# RL6955_IP_SVD register map
Vendor: Realtek
Registers are 32-bit, read-write, reset 0x0 unless marked. A register's access mark holds for its fields unless they carry their own. Offsets are from the block's base; [hi:lo] are bit positions; {n}, {i} and the like mark numbered series.

## AES_SHA_DMA_REG
Base 0x400C2000
Same registers: GDMA0_REG 0x41802000
{0x0+0x58*i} SAR{i} (i=0..7) — Channel {i} Source Address Register
  [31:0] SAR{i} — Source Address of DMA transfer.Updated after each source transfer. The SINC field in the CTLx register determines whether the address increments, or is left unchanged on every source transfer throughout the block transfer.
{0x4+0x58*i} CURR_SAR{i} ro (i=0..7) — The read back value is channel {i} source reading address at present
  [31:0] CURR_SAR{i} — The read back value is source reading address at present
{0x8+0x58*i} DAR{i} (i=0..7) — Channel {i} Destination Address Register
  [31:0] DAR{i} — Destination address of DMA transfer.Updated after each destination transfer. The DINC field in the CTLx register determines whether the address increments, or is left unchanged on every destination transfer throughout the block transfer.
{0xC+0x58*i} CURR_DAR{i} ro (i=0..7) — The read back value is channel {i} destination writing address at present
  [31:0] CURR_DAR{i} — The read back value is destination writing address at present
{0x10+0x58*i} LLP{i}_L (i=0..7) — Channel {i} low-32 bits Linked List Pointer Register
  [31:2] LLP{i}_L_LOC — Starting Address In Memory of next LLI if block chaining is enabled. Note that the two LSBs of the starting address are not stored because the address is assumed to be aligned to a 32-bit boundary.LLI accesses are always 32-bit accesses aligned to 32-bit boundaries and cannot be changed or programmed to anything other than 32-bit.
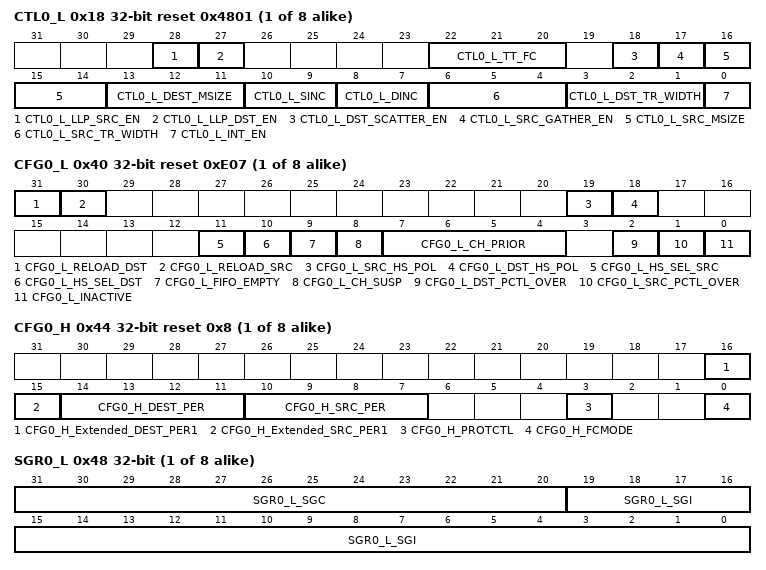
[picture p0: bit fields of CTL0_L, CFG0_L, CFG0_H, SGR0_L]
{0x18+0x58*i} CTL{i}_L reset 0x4801 (i=0..7) — Channel {i} low-32 bits Control Register
  [28] CTL{i}_L_LLP_SRC_EN — Block chanining is enabled on the source side only if the LLP_SRC_EN field id high and LLPx_L.LOC is non-zero; for more information,see 7.4.1.1 "Block Chaining Using Linked Lists" Dependencies:This field does not exist if the configuration parameterDMAC_CHx_MULTI_BLK_EN is not selected or if DMAC_CHx_HC_LLP is selected; in this case, the read-back value is always 0.
  [27] CTL{i}_L_LLP_DST_EN — Block chanining is enabled on the destination side only if the LLP_DST_EN field id high and LLPx_L.LOC is non-zero; for more information,see 7.4.1.1 "Block Chaining Using Linked Lists" Dependencies:This field does not exist if the configuration parameterDMAC_CHx_MULTI_BLK_EN is not selected or if DMAC_CHx_HC_LLP is selected; in this case, the read-back value is always 0.
  [22:20] CTL{i}_L_TT_FC — Transfer Type and Flow Control.The following transfer types are supported. • Memory to Memory • Memory to Peripheral • Peripheral to Memory • Peripheral to Peripheral Flow Control can be assigned to the RTK_DMAC, the source peripheral, or the destination peripheral. Table 6-4 lists the decoding for this field. For more information on transfer types and flow control, refer to "Setup/Operation of RTK_DMAC Transfers". Reset Value: 3'h0 Dependencies: If hardware handshake isn't support, then TT_FC can only be set to 3'b0. TT_FC[2] can only be read.
  [18] CTL{i}_L_DST_SCATTER_EN — Destination scatter enable bit:0 = Scatter disabled1 = Scatter enabledScatter on the destination side is applicable only when the CTLx_L.DINC bit indicates an incrementing address control and DARx should be aligned with DST_TR_WIDTH. Dependencies: This field does not exist if DMAC_CHx_DST_SCA_EN is not selected.
  [17] CTL{i}_L_SRC_GATHER_EN — Source gather enable bit: 0 = Gather disabled 1 = Gather enabled Gather on the source side is applicable only when the CTLx_L.SINC bit indicates an incrementing address control and SARx should be aligned with SRC_TR_WIDTH. Dependencies: This field does not exist if DMAC_CHx_SRC_GAT_EN is not selected.
  [16:14] CTL{i}_L_SRC_MSIZE — Source Burst Transaction Length. Number of data items, each of width CTLx_L.SRC_TR_WIDTH if source is not memory, otherwise each of width DMAC_TR_WIDTH_DEFAULT, to be read from the source every time a source burst transaction request is made from either the corresponding hardware or software handshaking interface. Read burst transaction length on bus (ARLen) will not exceed this value, but may be less than this value. If SINC is setted to "no change", this value should not be greater than 16 to conform to the AXI protocol. If enabled 'DMAC_CHx_MSIZE_BIGGER_THAN_FIFO_DEPTH' feature, to improve performance, can set CTLx_L.SRC_MSIZE to a high value to make DMAC send longer burst length command. But to avoid deadlock, if Source slave and Destination slave is the same slave, should not set CTLx_L.SRC_MSIZE over than FIFO_depth; Table 6-2-0 lists the decoding for this field.
  [13:11] CTL{i}_L_DEST_MSIZE — Destination Burst Transaction Length. Number of data items, each of width DATA_WIDTH, to be written to the destination every time a destination burst transaction request is made from either the corresponding hardware or software handshaking interface. Write burst transaction length on bus (AWLen) will not exceed this value, but may be less than this value. If DINC is setted to "no change", this value should not be greater than 16 to conform to the AXI protocol. If enabled 'DMAC_CHx_MSIZE_BIGGER_THAN_FIFO_DEPTH' feature, to improve performance, can set CTLx_L.SRC_MSIZE to a high value to make DMAC send longer burst length command. But to avoid deadlock, if Source slave and Destination slave is the same slave, should not set CTLx_L.SRC_MSIZE over than FIFO_depth; Table 6-2-1 lists the decoding for this field.
  [10:9] CTL{i}_L_SINC — Source Address Increment. Indicates whether to increment the source address on every source transfer. If the device is fetching data from a source peripheral FIFO with a fixed address, then set this field to "No change."If source is memory appointed by CTLx_L.TT_FC, and set SINC=No change, then SRC_TR_WIDTH must be set to BUS width. And DMAC will read data from the fixed memory address until block transfer finish, but It is not recommended to read memory like this, because some memory controller not support fixed burst transaction and may transform the fixed burst transaction to incremental burst transaction. 00 = Increment 01 =Not support 1x = No change NOTE: Incrementing is done for alignment to the next CTLx_L.SRC_TR_WIDTH boundary.
  [8:7] CTL{i}_L_DINC — Destination Address Increment. Indicates whether to increment destination address on every destination transfer. If your device is writing data to a destination peripheral FIFO with a fixed address, then set this field to "No change."If destination is memory appointed by CTLx_L.TT_FC, and set DINC=No change, then DST_TR_WIDTH must be set to BUS width. And DMAC will write data to the fixed memory address until block transfer finish, but It is not recommended to write memory like this, because some memory controller not support fixed burst transaction and may transform the fixed burst transaction to incremental burst transaction. 00 = Increment 01=Not Support 1x = No change NOTE: Incrementing is done for alignment to the next CTLx_L.DST_TR_WIDTH boundary.
  [6:4] CTL{i}_L_SRC_TR_WIDTH — Source Transfer Width. Table 6-3 lists the decoding for this field.It can't be mapped to AXI bus data width directly. Since AXI bus data width is fixed (such as 32bit/64bit), AXI use byte enable signal for byte/half word transfer (still burst). So, the SRC_TR_WIDTH is only used for total block data size calculation and streaming mode byte/half word transfer (for FIFO transfer). Note: SRC_TR_WIDTH must not be bigger than BUS width.
  [3:1] CTL{i}_L_DST_TR_WIDTH — Destination Transfer Width.Table 6-3 lists the decoding for this field. It can't be mapped to AXI bus data width directly. For a non-memory peripheral, typically the peripheral (destination) FIFO width.Note: DST_TR_WIDTH must not be bigger than BUS width
  [0] CTL{i}_L_INT_EN — Interrupt Enable Bit. If set, then all interrupt-generating sources are enabled. Functions as a global mask bit for all interrupts for the channel; raw* interrupt registers still assert if CTLx_L.INT_EN = 0.
{0x1C+0x58*i} CTL{i}_H access per field reset 0x2 (i=0..7) — Channel {i} high-32 bits Control Register
  [31:0] CTL{i}_H_TRANS_DATA_CNT ro — Data Transfered Count.Once the transfer starts, the read-back value is the total number of data bytes already write to destination memory or peripheral.
  [20:0] CTL{i}_H_BLOCK_TS wo — Block Transfer Size.When the RTK_DMAC is the flow controller, the user writes this field before the channel is enabled in order to indicate the block size. The number programmed into BLOCK_TS indicates the total number of single transactions to perform for every block transfer; a single transaction is mapped to a single AXI beat. This field is write-only, number of block size programmed into CTLx_H.BLOCK_TS can be read from SGRx_H.BLOCK_TS_L and DSRx_H.BLOCK_TS_H. Width: The width of the single transaction is determined by CTLX_L.SRC_TR_WIDTH.When the source or destination peripheral is assigned as the flow controller, then the maximum block size that can be read back saturates at DMAC_CHx_MAX_BLK_SIZE, but the actual block size can be greater. b = log2(DMAC_CHx_MAX_BLK_SIZE + 1) -1
{0x40+0x58*i} CFG{i}_L access per field reset 0xE07 (i=0..7) — Channel {i} low-32 bits Configuration Register
  [31] CFG{i}_L_RELOAD_DST rw — Automatic Destination Reload. The DARx register can be automatically reloaded from its initial value at the end of every block for multi-block transfers. A new block transfer is then initiated.This register does not exist if the configuration parameter DMAC_CHx_MULTI_BLK_EN is not selected; in this case, the read-back value is always 0.
  [30] CFG{i}_L_RELOAD_SRC rw — Automatic Source Reload. The SARx register can be automatically reloaded from its initial value at the end of every block for multi-block transfers. A new block transfer is then initiated. This field does not exist if the configuration parameter DMAC_CHx_MULTI_BLK_EN is not selected; in this case, the read-back value is always 0.
  [19] CFG{i}_L_SRC_HS_POL rw — Source Handshaking Interface Polarity. 0 = Active high 1 = Active low
  [18] CFG{i}_L_DST_HS_POL rw — Destination Handshaking Interface Polarity. 0 = Active high 1 = Active low For information on this, refer to "Handshaking Interface" .
  [11] CFG{i}_L_HS_SEL_SRC rw — Source Software or Hardware Handshaking Select. This register selects which of the handshaking interfaces - hardware or software - is active for source requests on this channel. 0 = Hardware handshaking interface. Software-initiated transaction requests are ignored. 1 = Software handshaking interface. Hardware-initiated transaction requests are ignored. If the source peripheral is memory, then this bit is ignored.
  [10] CFG{i}_L_HS_SEL_DST rw — Destination Software or Hardware Handshaking Select. This register selects which of the handshaking interfaces - hardware or software - is active for destination requests on this channel. 0 = Hardware handshaking interface. Software-initiated transaction requests are ignored. 1 = Software handshaking interface. Hardware- initiated transaction requests are ignored. If the destination peripheral is memory, then this bit is ignored.
  [9] CFG{i}_L_FIFO_EMPTY ro — Indicates if there is data left in the channel FIFO. 1 = Channel FIFO empty 0 = Channel FIFO not empty
  [8] CFG{i}_L_CH_SUSP rw — Channel Suspend. Suspends all DMA data transfers from the source until this bit is cleared. There is no guarantee that the current transaction will complete. Can also be used in conjunction with CFGx_l.INACTIVE to cleanly disable a channel without losing any data. 0 = Not suspended 1 = Suspend DMA transfer from the source. This field will be reset to 0 after "Disabling a Channel Prior to Transfer Completion" automatically by hardware.For more information, refer to "7.7 Disabling a Channel Prior to Transfer Completion" . Note: if user not define DMAC_CH*_SUPPORT_SUSPEND, it only can be readed.
  [7:4] CFG{i}_L_CH_PRIOR rw — Channel priority. RTK DMAC supports three kinds of channel priority now, fixed priority, round robin priority and programmable priority. The default way is fixed priority to reduce area, and channel0 has the highest priority, channel15 has the lowest priority. Changing the definition of parameter FIX_PRIORITY or Programmable_PRIORITY can change priority way. If RTK DMAC is configured to support Programmable priority, this field will be used to set priority between channels. CH_PRIOR's legal value is 0 ~ (DMAC_NUM_CHANNELS-1), and 0 is the highest priority value, (DMAC_NUM_CHANNELS-1) is the lowest priroty value. If more than one channel are set with the same priroty value, the channel with small channel number index has higher priority. If DMAC is configured to support fix priority or round-robin priority, this field is not exist. Note: if user not define ProgrammablePriority, it only can be readed.
  [2] CFG{i}_L_DST_PCTL_OVER ro — DMA destination bus protocol finish, indicating the current write command has finished.
  [1] CFG{i}_L_SRC_PCTL_OVER ro — DMA Source bus protocol finish, indicating the current read command has finished.
  [0] CFG{i}_L_INACTIVE ro — Indicates if the channel is inactive. Can be used in conjunction with CFGx_L.CH_SUSP to cleanly disable a channel when destination is peripheral. For more information, refer to "Disabling a Channel Prior to Transfer Completion" . 1 = Channel Inactive for axi interface 0 = Channel not Inactive for axi interface
{0x44+0x58*i} CFG{i}_H reset 0x8 (i=0..7) — Channel {i} high-32 bits Configuration Register
  [16] CFG{i}_H_Extended_DEST_PER1 — The extened 4th bit of DEST_PER when hardware handshake interfaces number is configured to 32.
  [15] CFG{i}_H_Extended_SRC_PER1 — The extened 4th bit of SRC_PER when hardware handshake interfaces number is configured to 32.
  [14:11] CFG{i}_H_DEST_PER — Assigns a hardware handshaking interface(0 - DMAC_NUM_HS_INT-1) to the destination of channel x if the FGx.HS_SEL_DST field is 0; otherwise, this field is ignored. The channel can then communicate with the destinationperipheral connected to that interface through the assignedhardware handshaking interface. NOTE1: For correct DMA operation, only one peripheral (sourceor destination) should be assigned to the same handshaking interface NOTE2: This field does not exist if the configuration parameterDMAC_NUM_HS_INT is set to 0.
  [10:7] CFG{i}_H_SRC_PER — Assigns a hardware handshaking interface(0 - DMAC_NUM_HS_INT-1) to the source of channel x if the CFGx.HS_SEL_SRC field is 0; otherwise, this field is ignored. The channel can then communicate with the source peripheral connected to that interface through the assigned hardware handshaking interface. NOTE1: For correct RTK_DMAC operation, only one peripheral (source or destination) should be assigned to the same handshaking interface. NOTE2: This field does not exist if the configuration parameter DMAC_NUM_HS_INT is set to 0.
  [3] CFG{i}_H_PROTCTL — Protection Control.Set the bit 35 to 0 will enable the channel secure DMA transfer. Set the bit 35 to 1 will enable the channel non-secure DMAC transfer. Note: if user not define DMAC_SECURE_MODE, it only can be readed.
  [0] CFG{i}_H_FCMODE — Flow Control Mode. Determines when source transaction requests are serviced when the Destination Peripheral is the flow controller. 0 = Source transaction requests are servied when they occur. Data pre-fetching is enabled. 1 = Source transaction requests are not serviced until a destination transaction request occurs. Data pre-fetching is disabled. Note: Please keep this bit 0 when Transfer Type and Flow Control is not "destination peripheral is the flow controller and transfer type is peripheral to peripheral" (TT_FC!=7).
{0x48+0x58*i} SGR{i}_L (i=0..7) — Channel {i} low-32 bits Source Gather Register
  [31:20] SGR{i}_L_SGC — Source gather count. Source contiguous transfer count between successive gather boundaries. Note: if user not define DMAC_SRC_GAT_EN, it only can be readed.
  [19:0] SGR{i}_L_SGI — Source gather interval. Note: if user not define DMAC_SRC_GAT_EN, it only can be readed.
{0x4C+0x58*i} SGR{i}_H ro reset 0x20000 (i=0..7) — Channel {i} high-32 bits Source Gather Register
  [31:16] SGR{i}_H_BLOCK_TS_L — Low 16-bits of Block Transfer Size.The number programmed into CTLX.BLOCK_TS, which indicates the total number of single transactions to perform for every block transfer, is separated into low 16 bits and high part. The low 16 bits is stored into SGRx.BLOCK_TS_L while the high part is stored into DSRx.BLOCK_TS_H Width: The width of the single transaction is determined by CTLx.SRC_TR_WIDTH.
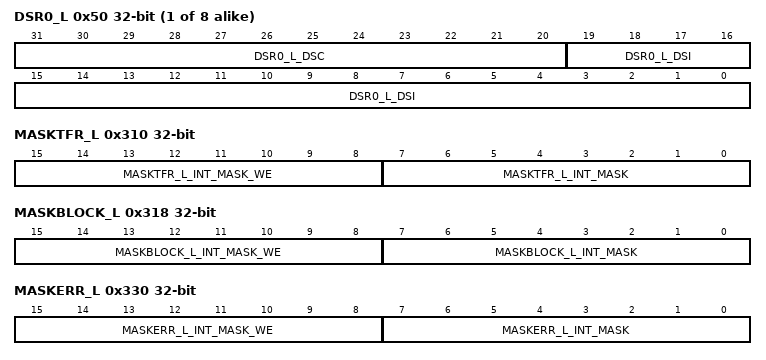
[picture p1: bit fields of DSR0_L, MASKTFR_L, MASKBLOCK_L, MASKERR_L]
{0x50+0x58*i} DSR{i}_L (i=0..7) — Channel {i} low-32 bits Destination Scatter Register
  [31:20] DSR{i}_L_DSC — Destination scatter count. Destination contiguous transfer count between successive scatter boundaries. Note: if user not define DMAC_DST_SCA_EN, it only can be readed.
  [19:0] DSR{i}_L_DSI — Destination scatter interval.Note: if user not define DMAC_DST_SCA_EN, it only can be readed.
{0x54+0x58*i} DSR{i}_H ro (i=0..7) — Channel {i} high-32 bits Destination Scatter Register
  [20:16] DSR{i}_H_BLOCK_TS_H — High part of Block Transfer SizeThe number programmed into CTLx_H.BLOCK_TS, which indicates the total number of single transactions to perform for every block transfer, is separated into low 16 bits and high 16 bits. The low 16-bits is stored into SGRx_H.BLOCK_TS_LOW while the high 16-bits is stored into DSRx_H.BLOCK_TS_HIGH Width: The width of the single transaction is determined by CTLx_L.SRC_TR_WIDTH.b = log2 (DMAC_CHx_MAX_BLK_SIZE). Dependencies: The maximum value of DMAC_CHx_MAX_BLK_SIZE is 2 ^ (31-log2 (DMAC_DATA_WIDTH/8)) - 1.
0x2C0 RAWTFR_L ro — Raw Status for IntTfr Interrupt
  [15:0] RAWTFR_L_Raw_Tfr — Raw interrupt status for chn0-chn15
0x2C8 RAWBLOCK_L ro — Raw Status for IntBlock Interrupt
  [15:0] RAWBLOCK_L_Raw_Block — Raw interrupt status for chn0-chn15
0x2E0 RAWERR_L ro — Raw Status for IntErr Interrupt(protocol error)
  [15:0] RAWERR_L_Raw_Err — Raw interrupt status for chn0-chn15. (Protocol error)
0x2E4 RAWERR_H ro — Raw Status for non-secure access secure register error if defined
  [15:0] RAWERR_H_Raw_Err — Raw interrupt status. (Non-secure access secure register error) if DMAC_SECURE_MODE has been defined; else it is reserved.
0x2E8 STATUSTFR_L ro — Status for IntTfr Interrupt
  [15:0] STATUSTFR_L_Status_Tfr — Interrupt status for chn0-chn15
0x2F0 STATUSBLOCK_L ro — Status for IntBlock Interrupt
  [15:0] STATUSBLOCK_L_Status_Block — Interrupt status for chn0-chn15
0x308 STATUSERR_L ro — Status for IntErr Interrupt
  [15:0] STATUSERR_L_Status_Err — Interrupt status for chn0-chn15. (Protocol error)
0x30C STATUSERR_H ro — Status for non-secure access secure register error if defined
  [15:0] STATUSERR_H_Status_Err — Interrupt status. (Non-secure access secure register error, Sec Error) if DMAC_SECURE_MODE has been defined; else it is reserved.
0x310 MASKTFR_L access per field — Mask for IntTfr Interrupt (chn0-7)
  [15:8] MASKTFR_L_INT_MASK_WE wo — Interrupt Mask Write Enable(chn0-chn7) 0 = write disabled 1 = write enabled
  [7:0] MASKTFR_L_INT_MASK rw — Interrupt Mask(chn0-chn7) 0 = masked 1 = unmasked
0x318 MASKBLOCK_L access per field — Mask for IntBlock Interrupt
  [15:8] MASKBLOCK_L_INT_MASK_WE wo — Interrupt Mask Write Enable(chn0-chn7) 0 = write disabled 1 = write enabled
  [7:0] MASKBLOCK_L_INT_MASK rw — Interrupt Mask(chn0-chn7) 0 = masked 1 = unmasked
0x330 MASKERR_L access per field — Mask for IntErr Interrupt
  [15:8] MASKERR_L_INT_MASK_WE wo — Interrupt Mask Write Enable(chn0-chn7) 0 = write disabled 1 = write enabled
  [7:0] MASKERR_L_INT_MASK rw — Interrupt Mask(chn0-chn7) 0 = masked 1 = unmasked
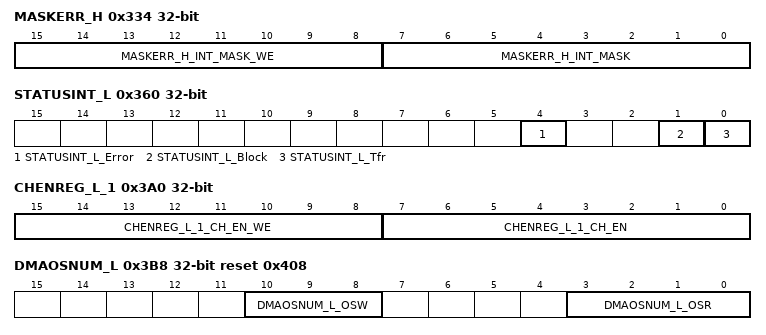
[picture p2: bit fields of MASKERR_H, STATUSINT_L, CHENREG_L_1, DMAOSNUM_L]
0x334 MASKERR_H access per field — Mask for non-secure access secure register error if defined
  [15:8] MASKERR_H_INT_MASK_WE wo — Interrupt Mask Write Enable(chn0-chn7) 0 = write disabled 1 = write enabled These bits only exist when DMAC_ SECURE_MODE has beed defined
  [7:0] MASKERR_H_INT_MASK rw — Interrupt Mask(chn0-chn7) 0 = masked 1 = unmasked These bits only exist when DMAC_ SECURE_MODE has beed defined
0x338 CLEARTFR_L wo — Clear for IntTfr Interrupt
  [15:0] CLEARTFR_L_Clear_Tfr — Interrupt clear for chn0-chn15 0 = no effect 1= clear interrupt
0x340 CLEARBLOCK_L wo — Clear for IntBlock Interrupt
  [15:0] CLEARBLOCK_L_Clear_Block — Interrupt clear for chn0-chn15
0x358 CLEARERR_L wo — Clear for IntErr Interrupt
  [15:0] CLEARERR_L_Clear_Protocol_Error — Interrupt clear for chn0-chn15. (Protocol error)
0x35C CLEARERR_H wo — Clear for non-secure access secure register error if defined
  [15:0] CLEARERR_H_Clear_Sec_Error — Interrupt clear for chn0-chn15 (Non-secure access secure register error, Sec Error) when DMAC_SECURE_MODE has beed defined, else it is reserved;
0x360 STATUSINT_L ro — Combined Interrupt Sataus Register
  [4] STATUSINT_L_Error — OR of the contents of StatusErr register.
  [1] STATUSINT_L_Block — OR of the contents of StatusBlock register.
  [0] STATUSINT_L_Tfr — OR of the contents of StatusTfr register.
0x398 DMACFGREG_L reset 0x1 — DMA low-32 bits Configuration Register
  [0] DMACFGREG_L_DMA_EN — RTK_DMAC Enable bit. 0 = RTK_DMAC Disabled 1 = RTK_DMAC Enabled
0x3A0 CHENREG_L_1 access per field — DMA low-32 bits Channel Enable Register if configed chn number is less than or equal to 8
  [15:8] CHENREG_L_1_CH_EN_WE wo — Channel enable write enable.
  [7:0] CHENREG_L_1_CH_EN rw — Enables/Disables the channel. Setting this bit enables a channel; clearing this bit disables the channel. 0 = Disable the Channel 1 = Enable the Channel The CHENREG_L.CH_EN bit is automatically cleared by hardware to disable the channel after the last AXI transfer of the DMA transfer to the destination has completed. Software can therefore poll this bit to determine when this channel is free for a new DMA transfer.
0x3A8 DMAIDREG_L ro reset 0x20240513 — DMA low-32 bits ID Register
  [31:0] DMAIDREG_L_DMA_ID — Hardcoded RTK_DMAC Peripheral ID
0x3B8 DMAOSNUM_L reset 0x408 — DMA low-32 bits Outstanding Number Register
  [10:8] DMAOSNUM_L_OSW — If the OSW number of DMAC is programmable, this register is writable. And DMAC will not issue new write command until OSW of DMAC is less than this value. If the OSW number is not programmable, this value is read as "4". And DMAC's OSW is fixed to 4. If user defines OSW_CNT, b = log2(OSW_CNT +1) +7; otherwise, b = log2(4+1) +7. bits 15: b+1 do not exist and read back as 0. Note: If write 0 to this register, DMAC can not issue any new write commands.
  [3:0] DMAOSNUM_L_OSR — If the OSR number of DMAC is programmable, this register is writable. And DMAC will not issue new read command until OSR of DMAC is less than this value. If the OSR number is not programmable, this value is read as "channel number". And DMAC does not limit the OSR number. If user defines OSR_CNT, b = log2(OSR_CNT +1); otherwise, b = log2(DMAH_NUM_CHANNELS +1) bits 7: b+1 do not exist and read back as 0. Note: If write 0 to this register, DMAC can not issue any new read commands.
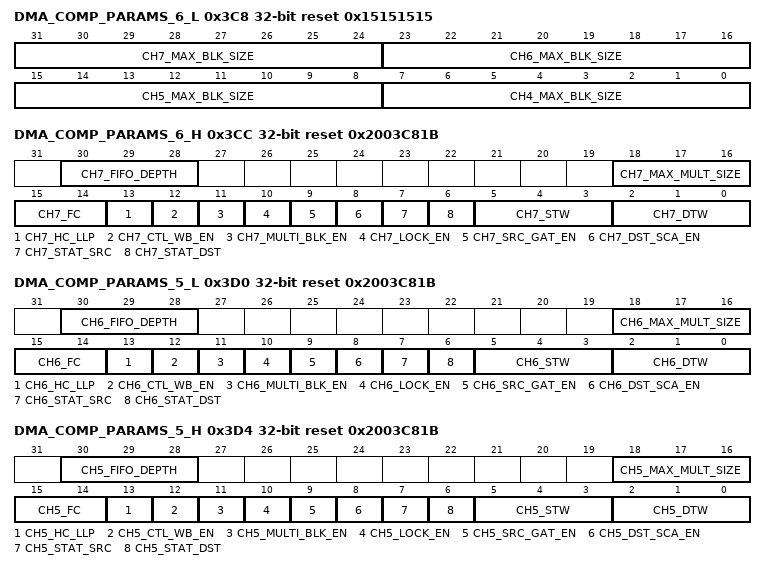
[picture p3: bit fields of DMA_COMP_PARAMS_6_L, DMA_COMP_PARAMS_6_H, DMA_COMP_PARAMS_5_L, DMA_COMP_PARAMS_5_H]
0x3C8 DMA_COMP_PARAMS_6_L ro reset 0x15151515 — Refer to the bit table in the description for it
  [8n-25:8n-32] CH{n}_MAX_BLK_SIZE (n=4..7) — The value of this register is derived from the DMAC_CH{n}_MAX_BLK_SIZE from config_form.vh CH{n}_MAX_BLK_SIZE = log2(DMAC_CH{n}_MAX_BLK_SIZE) + 1
0x3CC DMA_COMP_PARAMS_6_H ro reset 0x2003C81B — Refer to the bit table in the description for it
  [30:28] CH7_FIFO_DEPTH — The value of this register is derived from the DMAC_CH7_FIFO_DEPTH parameter. Default value is 0x0. CH7_FIFO_DEPTH = log2(DMAC_CH7_FIFO_DEPTH/8) 0x0 = 8 bytes 0x1 = 16 0x2 = 32 0x3 = 64 0x4 = 128 0x5 = Reserved 0x6 = Reserved 0x7 = Reserved
  [18:16] CH7_MAX_MULT_SIZE — The value of this register is derived from the DMAC_CH7_MULT_SIZE parameter. Maxium burst transaction size. CH7_MAX_MULT_SIZE = log2(256/DMAC_DATA_WIDTH) 0x3 = 32 bits 0x2 = 64 bits 0x1 = 128 bits
  [15:14] CH7_FC — The value of this register is derived from the DMAC_CH7_FC parameter. 0x0 = DMA 0x1 = SRC 0x2 = DST 0x3 = ANY
  [13] CH7_HC_LLP — The value of this register is derived from the DMAC_CH7_HC_LLP parameter. 0x0 = FALSE 0x1 = TRUE
  [12] CH7_CTL_WB_EN — The value of this register is derived from the DMAC_CH7_CTL_WB_EN parameter. 0x0 = FALSE 0x1 = TRUE
  [11] CH7_MULTI_BLK_EN — The value of this register is derived from the DMAC_CH7_CTL_WB_EN parameter. 0x0 = FALSE 0x1 = TRUE
  [10] CH7_LOCK_EN — The value of this register is derived from the DMAC_CH7_LOCK_EN parameter. 0x0 = FALSE 0x1 = TRUE
  [9] CH7_SRC_GAT_EN — The value of this register is derived from the DMAC_CH7_SRC_GAT_EN parameter. For a description of this parameter, refer to page 112. 0x0 = FALSE 0x1 = TRUE
  [8] CH7_DST_SCA_EN — The value of this register is derived from the DMAC_CH7_DST_SCA_EN parameter. 0x0 = FALSE 0x1 = TRUE
  [7] CH7_STAT_SRC — The value of this register is derived from the DMAC_CH7_STAT_SRC parameter. 0x0 = FALSE 0x1 = TRUE
  [6] CH7_STAT_DST — The value of this register is derived from the DMAC_CH7_STAT_DST parameter. 0x0 = FALSE 0x1 = TRUE
  [5:3] CH7_STW — The value of this register is derived from the DMAC_CH7_STW parameter. 0x0 = NO_HARDCODE 0x1 = 8 0x2 = 16 0x3 = 32 0x4 = 64 0x5 = 128 0x6 = 256 0x7 = reserved
  [2:0] CH7_DTW — The value of this register is derived from the DMAC_CH7_DTW parameter. 0x0 = NO_HARDCODE 0x1 = 8 0x2 = 16 0x3 = 32 0x4 = 64 0x5 = 128 0x6 = 256 0x7 = reserved
0x3D0 DMA_COMP_PARAMS_5_L ro reset 0x2003C81B — Refer to the bit table in the description for it
  [30:28] CH6_FIFO_DEPTH — The value of this register is derived from the DMAC_CH6_FIFO_DEPTH parameter. Default value is 0x0. 0x0 = 8 bytes 0x1 = 16 0x2 = 32 0x3 = 64 0x4 = 128 0x5 = Reserved 0x6 = Reserved 0x7 = Reserved
  [18:16] CH6_MAX_MULT_SIZE — The value of this register is derived from the DMAC_CH6_MULT_SIZE parameter. Maxium burst transaction size. CH6_MAX_MULT_SIZE = log2(256/DMAC_DATA_WIDTH) 0x3 = 32 bits 0x2 = 64 bits 0x1 = 128 bits
  [15:14] CH6_FC — The value of this register is derived from the DMAC_CH6_FC parameter. 0x0 = DMA 0x1 = SRC 0x2 = DST 0x3 = ANY
  [13] CH6_HC_LLP — The value of this register is derived from the DMAC_CH6_HC_LLP parameter. 0x0 = FALSE 0x1 = TRUE
  [12] CH6_CTL_WB_EN — The value of this register is derived from the DMAC_CH6_CTL_WB_EN parameter. 0x0 = FALSE 0x1 = TRUE
  [11] CH6_MULTI_BLK_EN — The value of this register is derived from the DMAC_CH6_MULTI_BLK_EN parameter. 0x0 = FALSE 0x1 = TRUE
  [10] CH6_LOCK_EN — The value of this register is derived from the DMAC_CH6_LOCK_EN parameter. 0x0 = FALSE 0x1 = TRUE
  [9] CH6_SRC_GAT_EN — The value of this register is derived from the DMAC_CH6_SRC_GAT_EN parameter. 0x0 = FALSE 0x1 = TRUE
  [8] CH6_DST_SCA_EN — The value of this register is derived from the DMAC_CH6_DST_SCA_EN parameter. 0x0 = FALSE 0x1 = TRUE
  [7] CH6_STAT_SRC — The value of this register is derived from the DMAC_CH6_STAT_SRC parameter. 0x0 = FALSE 0x1 = TRUE
  [6] CH6_STAT_DST — The value of this register is derived from the DMAC_CH6_STAT_DST parameter. 0x0 = FALSE 0x1 = TRUE
  [5:3] CH6_STW — The value of this register is derived from the DMAC_CH6_STW parameter. 0x0 = NO_HARDCODE 0x1 = 8 0x2 = 16 0x3 = 32 0x4 = 64 0x5 = 128 0x6 = 256 0x7 = reserved
  [2:0] CH6_DTW — The value of this register is derived from the DMAC_CH6_DTW parameter. 0x0 = NO_HARDCODE 0x1 = 8 0x2 = 16 0x3 = 32 0x4 = 64 0x5 = 128 0x6 = 256 0x7 = reserved
0x3D4 DMA_COMP_PARAMS_5_H ro reset 0x2003C81B — Refer to the bit table in the description for it
  [30:28] CH5_FIFO_DEPTH — The value of this register is derived from the DMAC_CH5_FIFO_DEPTH parameter. Default value is 0x0. 0x0 = 8 bytes 0x1 = 16 0x2 = 32 0x3 = 64 0x4 = 128 0x5 = Reserved 0x6 = Reserved 0x7 = Reserved
  [18:16] CH5_MAX_MULT_SIZE — The value of this register is derived from the DMAC_CH5_MULT_SIZE parameter. Maxium burst transaction size. CH5_MAX_MULT_SIZE = log2(256/DMAC_DATA_WIDTH) 0x3 = 32 bits 0x2 = 64 bits 0x1 = 128 bits
  [15:14] CH5_FC — The value of this register is derived from the DMAC_CH5_FC parameter. 0x0 = DMA 0x1 = SRC 0x2 = DST 0x3 = ANY
  [13] CH5_HC_LLP — The value of this register is derived from the DMAC_CH5_HC_LLP parameter. 0x0 = FALSE 0x1 = TRUE
  [12] CH5_CTL_WB_EN — The value of this register is derived from the DMAC_CH5_CTL_WB_EN parameter. 0x0 = FALSE 0x1 = TRUE
  [11] CH5_MULTI_BLK_EN — The value of this register is derived from the DMAC_CH5_MULTI_BLK_EN parameter. 0x0 = FALSE 0x1 = TRUE
  [10] CH5_LOCK_EN — The value of this register is derived from the DMAC_CH5_LOCK_EN parameter. 0x0 = FALSE 0x1 = TRUE
  [9] CH5_SRC_GAT_EN — The value of this register is derived from the DMAC_CH5_SRC_GAT_EN parameter. For a description of this parameter, refer to page 112. 0x0 = FALSE 0x1 = TRUE
  [8] CH5_DST_SCA_EN — The value of this register is derived from the DMAC_CH5_DST_SCA_EN parameter. 0x0 = FALSE 0x1 = TRUE
  [7] CH5_STAT_SRC — The value of this register is derived from the DMAC_CH5_STAT_SRC parameter. 0x0 = FALSE 0x1 = TRUE
  [6] CH5_STAT_DST — The value of this register is derived from the DMAC_CH5_STAT_DST parameter. 0x0 = FALSE 0x1 = TRUE
  [5:3] CH5_STW — The value of this register is derived from the DMAC_CH5_STW parameter. 0x0 = NO_HARDCODE 0x1 = 8 0x2 = 16 0x3 = 32 0x4 = 64 0x5 = 128 0x6 = 256 0x7 = reserved
  [2:0] CH5_DTW — The value of this register is derived from the DMAC_CH5_DTW parameter. 0x0 = NO_HARDCODE 0x1 = 8 0x2 = 16 0x3 = 32 0x4 = 64 0x5 = 128 0x6 = 256 0x7 = reserved
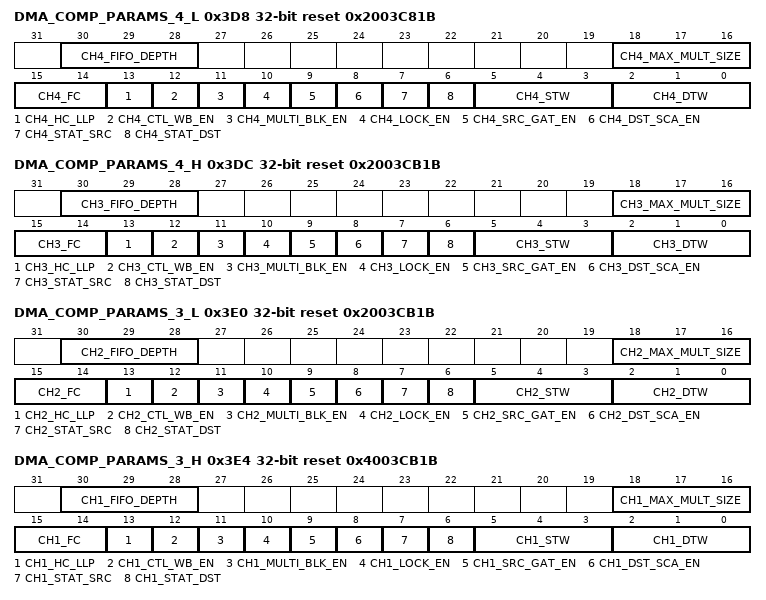
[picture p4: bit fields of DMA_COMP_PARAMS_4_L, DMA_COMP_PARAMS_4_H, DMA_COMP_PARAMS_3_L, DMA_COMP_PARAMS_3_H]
0x3D8 DMA_COMP_PARAMS_4_L ro reset 0x2003C81B — Refer to the bit table in the description for it
  [30:28] CH4_FIFO_DEPTH — The value of this register is derived from the DMAC_CH4_FIFO_DEPTH parameter. Default value is 0x0. 0x0 = 8 bytes 0x1 = 16 0x2 = 32 0x3 = 64 0x4 = 128 0x5 = Reserved 0x6 = Reserved 0x7 = Reserved
  [18:16] CH4_MAX_MULT_SIZE — The value of this register is derived from the DMAC_CH4_MULT_SIZE parameter. Maxium burst transaction size. CH4_MAX_MULT_SIZE = log2(256/DMAC_DATA_WIDTH) 0x3 = 32 bits 0x2 = 64 bits 0x1 = 128 bits
  [15:14] CH4_FC — The value of this register is derived from the DMAC_CH4_FC parameter. 0x0 = DMA 0x1 = SRC 0x2 = DST 0x3 = ANY
  [13] CH4_HC_LLP — The value of this register is derived from the DMAC_CH4_HC_LLP parameter. 0x0 = FALSE 0x1 = TRUE
  [12] CH4_CTL_WB_EN — The value of this register is derived from the DMAC_CH4_CTL_WB_EN parameter. 0x0 = FALSE 0x1 = TRUE
  [11] CH4_MULTI_BLK_EN — The value of this register is derived from the DMAC_CH4_MULTI_BLK_EN parameter. 0x0 = FALSE 0x1 = TRUE
  [10] CH4_LOCK_EN — The value of this register is derived from the DMAC_CH4_LOCK_EN parameter. 0x0 = FALSE 0x1 = TRUE
  [9] CH4_SRC_GAT_EN — The value of this register is derived from the DMAC_CH4_SRC_GAT_EN parameter. For a description of this parameter, refer to page 112.0x0 = FALSE 0x1 = TRUE
  [8] CH4_DST_SCA_EN — The value of this register is derived from the DMAC_CH4_DST_SCA_EN parameter. 0x0 = FALSE 0x1 = TRUE
  [7] CH4_STAT_SRC — The value of this register is derived from the DMAC_CH4_STAT_SRC parameter. 0x0 = FALSE 0x1 = TRUE
  [6] CH4_STAT_DST — The value of this register is derived from the DMAC_CH4_STAT_DST parameter. 0x0 = FALSE 0x1 = TRUE
  [5:3] CH4_STW — The value of this register is derived from the DMAC_CH4_STW parameter. 0x0 = NO_HARDCODE 0x1 = 8 0x2 = 16 0x3 = 32 0x4 = 64 0x5 = 128 0x6 = 256 0x7 = reserved
  [2:0] CH4_DTW — The value of this register is derived from the DMAC_CH4_DTW parameter. 0x0 = NO_HARDCODE 0x1 = 8 0x2 = 16 0x3 = 32 0x4 = 64 0x5 = 128 0x6 = 256 0x7 = reserved
0x3DC DMA_COMP_PARAMS_4_H ro reset 0x2003CB1B — Refer to the bit table in the description for it
  [30:28] CH3_FIFO_DEPTH — The value of this register is derived from the DMAC_CH3_FIFO_DEPTH parameter. Default value is 0x0. 0x0 = 8 bytes 0x1 = 16 0x2 = 32 0x3 = 64 0x4 = 128 0x5 = Reserved 0x6 = Reserved 0x7 = Reserved
  [18:16] CH3_MAX_MULT_SIZE — The value of this register is derived from the DMAC_CH3_MULT_SIZE parameter. Maxium burst transaction size. CH3_MAX_MULT_SIZE = log2(256/DMAC_DATA_WIDTH) 0x3 = 32 bits 0x2 = 64 bits 0x1 = 128 bits
  [15:14] CH3_FC — The value of this register is derived from the DMAC_CH3_FC parameter. 0x0 = DMA 0x1 = SRC 0x2 = DST 0x3 = ANY
  [13] CH3_HC_LLP — The value of this register is derived from the DMAC_CH3_HC_LLP parameter. 0x0 = FALSE 0x1 = TRUE
  [12] CH3_CTL_WB_EN — The value of this register is derived from the DMAC_CH3_CTL_WB_EN parameter. 0x0 = FALSE 0x1 = TRUE
  [11] CH3_MULTI_BLK_EN — The value of this register is derived from the DMAC_CH3_MULTI_BLK_EN parameter. 0x0 = FALSE 0x1 = TRUE
  [10] CH3_LOCK_EN — The value of this register is derived from the DMAC_CH3_LOCK_EN parameter. 0x0 = FALSE 0x1 = TRUE
  [9] CH3_SRC_GAT_EN — The value of this register is derived from the DMAC_CH3_SRC_GAT_EN parameter. 0x0 = FALSE 0x1 = TRUE
  [8] CH3_DST_SCA_EN — The value of this register is derived from the DMAC_CH3_DST_SCA_EN parameter. 0x0 = FALSE 0x1 = TRUE
  [7] CH3_STAT_SRC — The value of this register is derived from the DMAC_CH3_STAT_SRC parameter. 0x0 = FALSE 0x1 = TRUE
  [6] CH3_STAT_DST — The value of this register is derived from the DMAC_CH3_STAT_DST parameter. 0x0 = FALSE 0x1 = TRUE
  [5:3] CH3_STW — The value of this register is derived from the DMAC_CH3_STW parameter. 0x0 = NO_HARDCODE 0x1 = 8 0x2 = 16 0x3 = 32 0x4 = 64 0x5 = 128 0x6 = 256 0x7 = reserved
  [2:0] CH3_DTW — The value of this register is derived from the DMAC_CH3_DTW parameter. 0x0 = NO_HARDCODE 0x1 = 8 0x2 = 16 0x3 = 32 0x4 = 64 0x5 = 128 0x6 = 256 0x7 = reserved
0x3E0 DMA_COMP_PARAMS_3_L ro reset 0x2003CB1B — Refer to the bit table in the description for it
  [30:28] CH2_FIFO_DEPTH — The value of this register is derived from the DMAC_CH2_FIFO_DEPTH parameter. Default value is 0x0. 0x0 = 8 bytes 0x1 = 16 0x2 = 32 0x3 = 64 0x4 = 128 0x5 = Reserved 0x6 = Reserved 0x7 = Reserved
  [18:16] CH2_MAX_MULT_SIZE — The value of this register is derived from the DMAC_CH2_MULT_SIZE parameter. Maxium burst transaction size. CH2_MAX_MULT_SIZE = log2(256/DMAC_DATA_WIDTH) 0x3 = 32 bits 0x2 = 64 bits 0x1 = 128 bits
  [15:14] CH2_FC — The value of this register is derived from the DMAC_CH2_FC parameter. 0x0 = DMA 0x1 = SRC 0x2 = DST 0x3 = ANY
  [13] CH2_HC_LLP — The value of this register is derived from the DMAC_CH2_HC_LLP parameter. 0x0 = FALSE 0x1 = TRUE
  [12] CH2_CTL_WB_EN — The value of this register is derived from the DMAC_CH2_CTL_WB_EN parameter. 0x0 = FALSE 0x1 = TRUE
  [11] CH2_MULTI_BLK_EN — The value of this register is derived from the DMAC_CH2_MULTI_BLK_EN parameter. 0x0 = FALSE 0x1 = TRUE
  [10] CH2_LOCK_EN — The value of this register is derived from the DMAC_CH2_LOCK_EN parameter. 0x0 = FALSE 0x1 = TRUE
  [9] CH2_SRC_GAT_EN — The value of this register is derived from the DMAC_CH2_SRC_GAT_EN parameter. For a description of this parameter, refer to page 112. 0x0 = FALSE 0x1 = TRUE
  [8] CH2_DST_SCA_EN — The value of this register is derived from the DMAC_CH2_DST_SCA_EN parameter. 0x0 = FALSE 0x1 = TRUE
  [7] CH2_STAT_SRC — The value of this register is derived from the DMAC_CH2_STAT_SRC parameter. 0x0 = FALSE 0x1 = TRUE
  [6] CH2_STAT_DST — The value of this register is derived from the DMAC_CH2_STAT_DST parameter. 0x0 = FALSE 0x1 = TRUE
  [5:3] CH2_STW — The value of this register is derived from the DMAC_CH2_STW parameter. 0x0 = NO_HARDCODE 0x1 = 8 0x2 = 16 0x3 = 32 0x4 = 64 0x5 = 128 0x6 = 256 0x7 = reserved
  [2:0] CH2_DTW — The value of this register is derived from the DMAC_CH2_DTW parameter. 0x0 = NO_HARDCODE 0x1 = 8 0x2 = 16 0x3 = 32 0x4 = 64 0x5 = 128 0x6 = 256 0x7 = reserved
0x3E4 DMA_COMP_PARAMS_3_H ro reset 0x4003CB1B — Refer to the bit table in the description for it
  [30:28] CH1_FIFO_DEPTH — The value of this register is derived from the DMAC_CH1_FIFO_DEPTH parameter. Default value is 0x0. 0x0 = 8 bytes 0x1 = 16 0x2 = 32 0x3 = 64 0x4 = 128 0x5 = Reserved 0x6 = Reserved 0x7 = Reserved
  [18:16] CH1_MAX_MULT_SIZE — The value of this register is derived from the DMAC_CH1_MULT_SIZE parameter. Maxium burst transaction size. CH1_MAX_MULT_SIZE = log2(256/DMAC_DATA_WIDTH) 0x3 = 32 bits 0x2 = 64 bits 0x1 = 128 bits
  [15:14] CH1_FC — The value of this register is derived from the DMAC_CH1_FC parameter. 0x0 = DMA 0x1 = SRC 0x2 = DST 0x3 = ANY
  [13] CH1_HC_LLP — The value of this register is derived from the DMAC_CH1_HC_LLP parameter. 0x0 = FALSE 0x1 = TRUE
  [12] CH1_CTL_WB_EN — The value of this register is derived from the DMAC_CH1_CTL_WB_EN parameter. 0x0 = FALSE 0x1 = TRUE
  [11] CH1_MULTI_BLK_EN — The value of this register is derived from the DMAC_CH1_MULTI_BLK_EN parameter. 0x0 = FALSE 0x1 = TRUE
  [10] CH1_LOCK_EN — The value of this register is derived from the DMAC_CH1_LOCK_EN parameter. 0x0 = FALSE 0x1 = TRUE
  [9] CH1_SRC_GAT_EN — The value of this register is derived from the DMAC_CH1_SRC_GAT_EN parameter. 0x0 = FALSE 0x1 = TRUE
  [8] CH1_DST_SCA_EN — The value of this register is derived from the DMAC_CH1_DST_SCA_EN parameter. 0x0 = FALSE 0x1 = TRUE
  [7] CH1_STAT_SRC — The value of this register is derived from the DMAC_CH1_STAT_SRC parameter. 0x0 = FALSE 0x1 = TRUE
  [6] CH1_STAT_DST — The value of this register is derived from the DMAC_CH1_STAT_DST parameter. 0x0 = FALSE 0x1 = TRUE
  [5:3] CH1_STW — The value of this register is derived from the DMAC_CH1_STW parameter. 0x0 = NO_HARDCODE 0x1 = 8 0x2 = 16 0x3 = 32 0x4 = 64 0x5 = 128 0x6 = 256 0x7 = reserved
  [2:0] CH1_DTW — The value of this register is derived from the DMAC_CH1_DTW parameter. 0x0 = NO_HARDCODE 0x1 = 8 0x2 = 16 0x3 = 32 0x4 = 64 0x5 = 128 0x6 = 256 0x7 = reserved
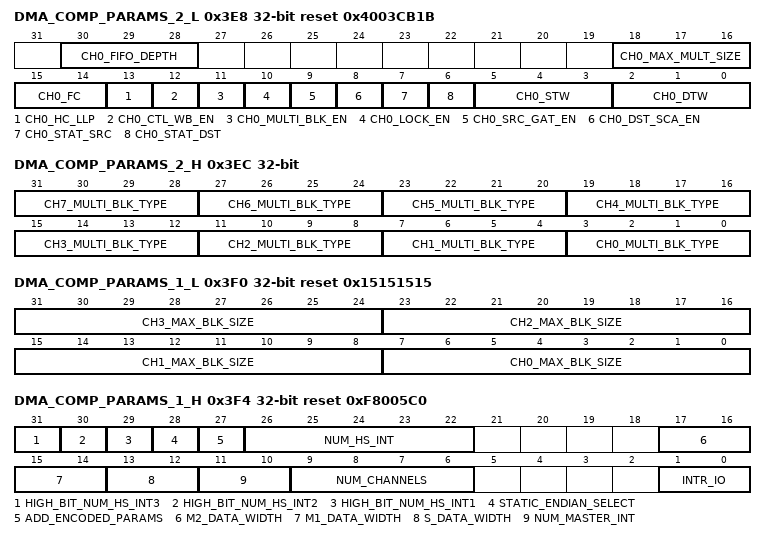
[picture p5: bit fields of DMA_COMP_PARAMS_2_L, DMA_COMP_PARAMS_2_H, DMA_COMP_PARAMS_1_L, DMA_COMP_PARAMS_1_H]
0x3E8 DMA_COMP_PARAMS_2_L ro reset 0x4003CB1B — Refer to the bit table in the description for it
  [30:28] CH0_FIFO_DEPTH — The value of this register is derived from the DMAC_CH0_FIFO_DEPTH parameter. Default value is 0x0. 0x0 = 8 bytes 0x1 = 16 0x2 = 32 0x3 = 64 0x4 = 128 0x5 = Reserved 0x6 = Reserved 0x7 = Reserved
  [18:16] CH0_MAX_MULT_SIZE — The value of this register is derived from the DMAC_CH0_MULT_SIZE parameter. Maxium burst transaction size. CH0_MAX_MULT_SIZE = log2(256/DMAC_DATA_WIDTH) 0x3 = 32 bits 0x2 = 64 bits 0x1 = 128 bits
  [15:14] CH0_FC — The value of this register is derived from the DMAC_CH0_FC parameter. 0x0 = DMA 0x1 = SRC 0x2 = DST 0x3 = ANY
  [13] CH0_HC_LLP — The value of this register is derived from the DMAC_CH0_HC_LLP parameter. 0x0 = FALSE 0x1 = TRUE
  [12] CH0_CTL_WB_EN — The value of this register is derived from the DMAC_CH0_CTL_WB_EN parameter. 0x0 = FALSE 0x1 = TRUE
  [11] CH0_MULTI_BLK_EN — The value of this register is derived from the DMAC_CH0_MULTI_BLK_EN parameter. 0x0 = FALSE 0x1 = TRUE
  [10] CH0_LOCK_EN — The value of this register is derived from the DMAC_CH0_LOCK_EN parameter. 0x0 = FALSE 0x1 = TRUE
  [9] CH0_SRC_GAT_EN — The value of this register is derived from the DMAC_CH0_SRC_GAT_EN parameter. For a description of this parameter, refer to page 112. 0x0 = FALSE 0x1 = TRUE
  [8] CH0_DST_SCA_EN — The value of this register is derived from the DMAC_CH0_DST_SCA_EN parameter. 0x0 = FALSE 0x1 = TRUE
  [7] CH0_STAT_SRC — The value of this register is derived from the DMAC_CH0_STAT_SRC parameter. 0x0 = FALSE 0x1 = TRUE
  [6] CH0_STAT_DST — The value of this register is derived from the DMAC_CH0_STAT_DST parameter. 0x0 = FALSE 0x1 = TRUE
  [5:3] CH0_STW — The value of this register is derived from the DMAC_CH0_STW parameter. 0x0 = NO_HARDCODE 0x1 = 8 0x2 = 16 0x3 = 32 0x4 = 64 0x5 = 128 0x6 = 256 0x7 = reserved
  [2:0] CH0_DTW — The value of this register is derived from the DMAC_CH0_DTW parameter. 0x0 = NO_HARDCODE 0x1 = 8 0x2 = 16 0x3 = 32 0x4 = 64 0x5 = 128 0x6 = 256 0x7 = reserved
0x3EC DMA_COMP_PARAMS_2_H ro — Refer to the bit table in the description for it
  [4n+3:4n] CH{n}_MULTI_BLK_TYPE (n=0..7) — The values of these bit fields are derived from the DMAC_CHx_MULTI_BLK_TYPE parameter. 0x0 = NO_HARDCODE 0x1 = CONT_RELOAD 0x2 = RELOAD_CONT 0x3 = RELOAD_RELOAD 0x4 = CONT_LLP 0x5 = RELOAD_LLP 0x6 = LLP_CONT 0x7 = LLP_RELOAD 0x8 = LLP_LLP
0x3F0 DMA_COMP_PARAMS_1_L ro reset 0x15151515 — Refer to the bit table in the description for it
  [8n+7:8n] CH{n}_MAX_BLK_SIZE (n=0..3) — The value of this register is derived from the DMAC_CH{n}_MAX_BLK_SIZE from config_form.vh CH{n}_MAX_BLK_SIZE = log2(DMAC_CH{n}_MAX_BLK_SIZE) + 1
0x3F4 DMA_COMP_PARAMS_1_H ro reset 0xF8005C0 — Refer to the bit table in the description for it
  [31] HIGH_BIT_NUM_HS_INT3 — Number of hardware handshake interfaces. If it is 128, this bit read value is 1.
  [30] HIGH_BIT_NUM_HS_INT2 — Number of hardware handshake interfaces. If it is greater than 63 and less than 128, this bit read value is 1.
  [29] HIGH_BIT_NUM_HS_INT1 — Number of hardware handshake interfaces. If it is greater than 31 and less than 64, this bit read value is 1.
  [28] STATIC_ENDIAN_SELECT — The value of this register is derived from the DMAC_STATIC_ENDIAN_SELECT parameter. 0 = FALSE (dynamic endian fixed) 1 = TRUE (not supported)
  [27] ADD_ENCODED_PARAMS — The value of this register is derived from the DMAC_ADD_ENCODED_PARAMS parameter. 0 = FALSE 1 = TRUE
  [26:22] NUM_HS_INT — Number of hardware handshake interfaces. The value of this register is derived from the DMAC_NUM_HS_INT parameter. NUM_HAS_INT = DMAC_NUM_HS_INT[4:0] 0x00 = 0 ... 0x10 = 16
  [17:16] M2_DATA_WIDTH — AXI Master2 data width. The value of this register is derived from the DMAC_M2_DATA_WIDTH parameter. Master2 data width should be equal to that of Master 1. M2_DATA_WIDTH = log2(DMAC_DATA_WIDTH/32) 0x0 = 32 bits 0x1 = 64 bits 0x2 = 128 bits 0x3 = Reserved
  [15:14] M1_DATA_WIDTH — AXI Master1 data width. The value of this register is derived from the DMAC_M1_DATA_WIDTH parameter. Master1 data width should be equal to that of Master 2. M1_DATA_WIDTH = log2(DMAC_DATA_WIDTH/32) 0x0 = 32 bits 0x1 = 64 bits 0x2 = 128 bits 0x3 = Reserved
  [13:12] S_DATA_WIDTH — APB slave interface data width.The value of this register is derived from the DMAC_S_DATA_WIDTH parameter. The width is fixed to 32 bits for now. S_DATA_WIDTH = log2(DMAC_DATA_WIDTH/32) 0x0 = 32 bits 0x1 = Reserved 0x2 = Reserved 0x3 = Reserved
  [11:10] NUM_MASTER_INT — Number of master interface. The value of this register is derived from the DMAC_NUM_MASTER_INT parameter. This value is fixed to 1 (only 2 AXI masters supported now.) 0x0 = Reserved 0x1 = 2 0x2 = Reserved 0x3 = Reserved
  [9:6] NUM_CHANNELS — Number of channels. The value of this register is derived from the DMAC_NUM_CHASNNELS parameter. NUM_CHANNELS = DMAC_NUM_CHASNNELS -1 0x0 = 1 ... 0xf = 16
  [1:0] INTR_IO — Interrupt output format.The value of this register is derived from the DMAC_INTR_IO parameter. 0x0 = ALL 0x1 = TYPE 0x2 = COMBINED 0x3 = reserved
0x3F8 DMA_COMPONENT_ID_REGS_L ro reset 0x20240513 — DMAC ID
  [31:0] DMA_COMPONENT_ID — DMAC ID (release_date_. Configure it in config form.
0x3FC DMA_COMPONENT_ID_REGS_H ro reset 0x482F5D83 — It is obtained from the high 32 bits from git logs in git server.
  [31:0] RTL_GIT_VER
